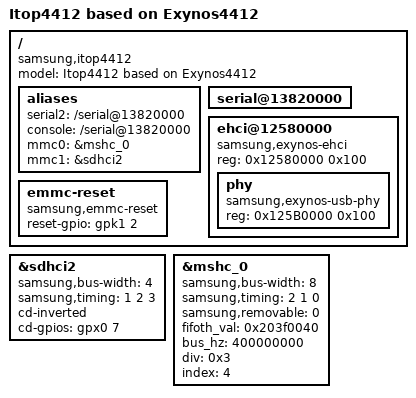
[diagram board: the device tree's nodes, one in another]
// SPDX-License-Identifier: GPL-2.0+
/*
 * Itop4412 board device tree source
 *
 * Copyright (c) 2014 Samsung Electronics Co., Ltd.
 *		http://www.samsung.com
 */

/dts-v1/;
#include "exynos4412.dtsi"
#include <dt-bindings/gpio/gpio.h>

/ {
	model = "Itop4412 based on Exynos4412";
	compatible = "samsung,itop4412", "samsung,exynos4412";

	aliases {
		serial2 = "/serial@13820000";
		console = "/serial@13820000";
		mmc0 = &mshc_0;
		mmc1 = &sdhci2;
	};

	serial@13820000 {
		status = "okay";
	};

	ehci@12580000 {
		compatible = "samsung,exynos-ehci";
		reg = <0x12580000 0x100>;
		#address-cells = <1>;
		#size-cells = <1>;
		phy {
			compatible = "samsung,exynos-usb-phy";
			reg = <0x125B0000 0x100>;
		};
	};

	emmc-reset {
		compatible = "samsung,emmc-reset";
		reset-gpio = <&gpk1 2 0>;
	};
};

&sdhci2 {
	samsung,bus-width = <4>;
	samsung,timing = <1 2 3>;
	cd-inverted;
	cd-gpios = <&gpx0 7 0>;
	status = "okay";
};

&mshc_0 {
	samsung,bus-width = <8>;
	samsung,timing = <2 1 0>;
	samsung,removable = <0>;
	fifoth_val = <0x203f0040>;
	bus_hz = <400000000>;
	div = <0x3>;
	index = <4>;
	status = "okay";
};
